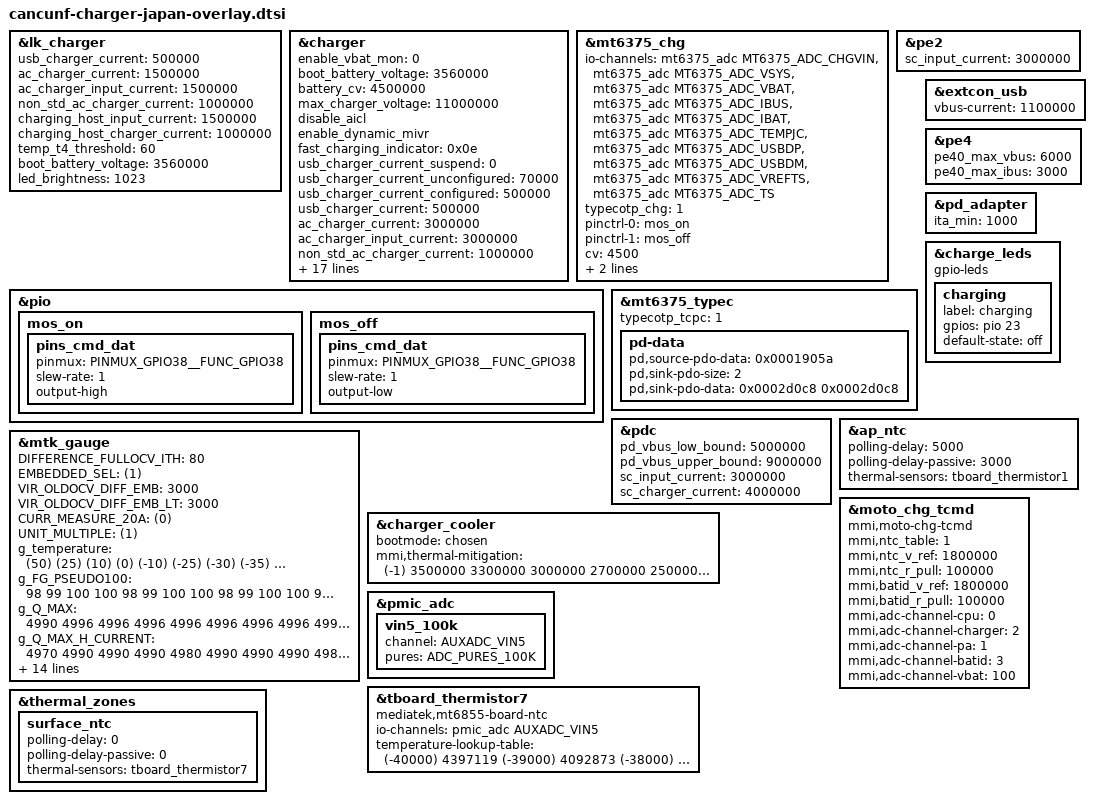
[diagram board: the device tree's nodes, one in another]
/*
 * Copyright (c) 2021 MediaTek Inc.
 *
 * This program is free software; you can redistribute it and/or modify
 * it under the terms of the GNU General Public License version 2 as
 * published by the Free Software Foundation.
 *
 * This program is distributed in the hope that it will be useful,
 * but WITHOUT ANY WARRANTY; without even the implied warranty of
 * MERCHANTABILITY or FITNESS FOR A PARTICULAR PURPOSE.  See the
 * GNU General Public License for more details.
 */

#include <dt-bindings/iio/adc/mediatek,mt6375_adc.h>

&lk_charger {
	/* charging current */
	usb_charger_current = <500000>;
	ac_charger_current = <1500000>;
	ac_charger_input_current = <1500000>;
	non_std_ac_charger_current = <1000000>;
	charging_host_input_current = <1500000>;
	charging_host_charger_current = <1000000>;

	temp_t4_threshold = <60>;

	boot_battery_voltage = <3560000>;
};

&charger {
        /* sw jeita */
        enable_vbat_mon = <0>;

	/* common */
        boot_battery_voltage = <3560000>;
	battery_cv = <4500000>;
	max_charger_voltage = <11000000>;
//	min_charger_voltage = <4600000>;

        disable_aicl;
        enable_dynamic_mivr;

	/*pdc && pe2*/
	fast_charging_indicator = <0x0e>;
	/*swchg + 1CP*/
	//charger_configuration= <3>;

	/* charging current */
	usb_charger_current_suspend = <0>;
	usb_charger_current_unconfigured = <70000>;
	usb_charger_current_configured = <500000>;
	usb_charger_current = <500000>;
	ac_charger_current = <3000000>;
	ac_charger_input_current = <3000000>;
	non_std_ac_charger_current = <1000000>;
	charging_host_charger_current = <1500000>;
	apple_1_0a_charger_current = <650000>;
	apple_2_1a_charger_current = <800000>;
	ta_ac_charger_current = <2000000>;
	typec_limit_aicr = <3000000>;
	typecotp_charger = <1>;

	/*mmi config*/
	mmi,iterm-ma = <243>;
	mmi,mmi-temp-zones = <0 4200 1000 0>,
			<10 4500 3000 1000>,
			<15 4500 3000 3000>,
			<45 4500 4000 4000>,
			<60 4200 4000 0>;
	mmi,mmi-ffc-zones = <0 4200 243>,
			<10 4500 243>,
			<15 4500 243>,
			<25 4530 506>,
			<35 4530 560>,
			<45 4530 965>,
			<60 4200 243>;
	mmi,enable-charging-limit;
	mmi,upper-limit-capacity = <75>;
	mmi,lower-limit-capacity = <70>;
	mmi,min-cp-therm-current-ua = <1600000>;
};

&mt6375_chg {
		io-channels = <&mt6375_adc MT6375_ADC_CHGVIN>,
				      <&mt6375_adc MT6375_ADC_VSYS>,
				      <&mt6375_adc MT6375_ADC_VBAT>,
				      <&mt6375_adc MT6375_ADC_IBUS>,
				      <&mt6375_adc MT6375_ADC_IBAT>,
				      <&mt6375_adc MT6375_ADC_TEMPJC>,
				      <&mt6375_adc MT6375_ADC_USBDP>,
				      <&mt6375_adc MT6375_ADC_USBDM>,
		              <&mt6375_adc MT6375_ADC_VREFTS>,
					  <&mt6375_adc MT6375_ADC_TS>;
		typecotp_chg = <1>;
		pinctrl-names = "mos_on","mos_off";
		pinctrl-0 = <&mos_on>;
		pinctrl-1 = <&mos_off>;

	cv = <4500>;
	ircmp_r = <0>;
	ircmp_v = <0>;
};

&pio {
	mos_on: mos_on {
		pins_cmd_dat {
			pinmux = <PINMUX_GPIO38__FUNC_GPIO38>;
			slew-rate = <1>;
			output-high;
		};
	};
	mos_off: mos_off {
		pins_cmd_dat {
			pinmux = <PINMUX_GPIO38__FUNC_GPIO38>;
			slew-rate = <1>;
			output-low;
		};
	};
};
/*
&pdc {
	sc_input_current = <3000000>;
};
*/
&pe2 {
	sc_input_current = <3000000>;
};

&mt6375_typec {
	typecotp_tcpc = <1>;
	pd-data {
		/* 5V, 900ma */
		pd,source-pdo-data = <0x0001905a>;
		/* 9V, 2A */
		pd,sink-pdo-size = <2>;
                pd,sink-pdo-data = <0x0002d0c8 0x0002d0c8> ;
	};
};

&extcon_usb {
	vbus-current = <1100000>;
};


&pdc {
	pd_vbus_low_bound = <5000000>;
	pd_vbus_upper_bound = <9000000>;

	sc_input_current = <3000000>;
	sc_charger_current = <4000000>;
};



&pe4 {
	pe40_max_vbus = <6000>;
	pe40_max_ibus = <3000>;
};


&pd_adapter{
	ita_min = <1000>;
};

&mtk_gauge {

	DIFFERENCE_FULLOCV_ITH = <80>;  /*gauge cut-off current, should overtop ieoc 50ma*/
	EMBEDDED_SEL = <(1)>;  /*embedded battery,don't remove the battery for user*/
	VIR_OLDOCV_DIFF_EMB = <3000>; /*0.1mv*/
	VIR_OLDOCV_DIFF_EMB_LT = <3000>; /*0.1mv*/
        CURR_MEASURE_20A = <(0)>;
        UNIT_MULTIPLE = <(1)>;

	/* battery prop */
	g_temperature = <(50) (25) (10) (0) (-10) (-25) (-30) (-35) (-40) (-45)>;
	g_FG_PSEUDO100 = <98 99 100 100
		98 99 100 100
		98 99 100 100
		98 99 100 100
		98 99 100 100
		100 100 100 100
		100 100 100 100
		100 100 100 100
		100 100 100 100
		100 100 100 100>;

	g_Q_MAX = <4990 4996 4996 4996
		4996 4996 4996 4996
		4996 4996 4996 4996
		4996 4996 4996 4996
		4990 4996 4996 4996
		4990 4996 4996 4996
		4990 4996 4996 4996
		4990 4996 4996 4996
		4990 4996 4996 4996
		4990 4996 4996 4996>;

	g_Q_MAX_H_CURRENT = <4970 4990 4990 4990
		4980 4990 4990 4990
		4980 4990 4990 4990
		4980 4990 4990 4990
		4970 4990 4990 4990
		4970 4990 4990 4990
		4970 4990 4990 4990
		4970 4990 4990 4990
		4970 4990 4990 4990
		4970 4990 4990 4990>;

	/*vboot voltage for gauge 0%*/
	g_PMIC_MIN_VOL_row = <4>;
	g_PMIC_MIN_VOL_col = <10>;
	g_PMIC_MIN_VOL = <32000  32000  33500  33500
		32000  32000  33000  33000
		33000  33000  33000  33000
		32200  32200  32200  32200
		31360  31360  31360  31360
		31000  31000  31000  31000
		31000  31000  31000  31000
		31000  31000  31000  31000
		31000  31000  31000  31000
		31000  31000  31000  31200>;

	/*Pseudo1 hide percentage*/
	g_QMAX_SYS_VOL_row = <4>;
	g_QMAX_SYS_VOL_col = <10>;
	g_QMAX_SYS_VOL = <32500  32500  34950  34950
		32500  32500  34950  34950
		34250  34250  34250  34250
		34250  34250  34250  34250
		34250  34250  34250  34250
		34250  34250  34250  34250
		32800  32800  32800  32800
		32800  32800  32800  32800
		32800  32800  32800  32800
		32800  32800  32800  32800>;

	SHUTDOWN_1_TIME = <(30)>;
	ACTIVE_TABLE = <(5)>;
	R_FG_VALUE = <(5)>;
	NO_BAT_TEMP_COMPENSATE = <(1)>;
//	df-serialnum = "SB18D61156";
	df-serialnum = "SB18D86478";
	CAR_TUNE_VALUE = <(99)>;
	#include "bat_setting/mt6855_battery_pc50_atl_5000mah.dtsi"
	#include "bat_setting/mt6855_battery_pc50_scud_5000mah.dtsi"
//	#include "bat_setting/mt6855_battery_table_lwn_5000.dtsi"
//	#include "bat_setting/mt6855_battery_table_ff.dtsi"

};

/*
&i2c9 {
       status = "okay";
       sc8551-charger@66{
               compatible = "sc,sc8551-standalone";
               reg = <0x66>;
               sc,sc8551,irq-gpio = <&pio 0 0>;
               sc,sc8551,bat-ovp-disable = <0>;
               sc,sc8551,bat-ocp_disable = <0>;
               sc,sc8551,bus-ocp-disable = <0>;

*/
               /*sc,sc8551,bat-ovp-disable = <0>;
               sc,sc8551,bat-ocp_disable = <0>;
               sc,sc8551,bus-ocp-disable = <0>;*/
/*
               sc,sc8551,bat-ovp-threshold = <4600>;
               sc,sc8551,bat-ocp-threshold = <8000>;

               sc,sc8551,bus-ovp-threshold = <12000>;
               sc,sc8551,bus-ocp-threshold = <3750>;

               sc,sc8551,ac-ovp-threshold = <12000>;
               sc,sc8551,sense-resistor-mohm = <5>;
       };
};
*/

&charge_leds {
	compatible = "gpio-leds";

	charging {
		label = "charging";
		gpios = <&pio 23 0x0>;
		default-state = "off";
	};
};

&charger_cooler {
	bootmode = <&chosen>;
	mmi,thermal-mitigation = <(-1) 3500000 3300000 3000000 2700000 2500000 2200000 2000000 1800000
				1500000 1000000 800000 500000>;
};


&ap_ntc {
	polling-delay = <5000>;
	polling-delay-passive = <3000>;
 	thermal-sensors = <&tboard_thermistor1>;
};


&moto_chg_tcmd {
	compatible = "mmi,moto-chg-tcmd";
	status = "okay";

	mmi,ntc_table = <1>;
	mmi,ntc_v_ref = <1800000>;
	mmi,ntc_r_pull = <100000>;

	mmi,batid_v_ref = <1800000>;
	mmi,batid_r_pull = <100000>;

	mmi,adc-channel-cpu = <0>;
	mmi,adc-channel-charger = <2>;
	mmi,adc-channel-pa = <1>;
	mmi,adc-channel-batid = <3>;
	mmi,adc-channel-vbat = <100>;
};

&lk_charger {
       /* LCD brightness*/
       led_brightness = <1023>;
};

&pmic_adc {
	vin5_100k {
		channel = <AUXADC_VIN5>;
		pures = <ADC_PURES_100K>;
	};
};

&tboard_thermistor7 {
	compatible = "mediatek,mt6855-board-ntc";
	status = "okay";
	#thermal-sensor-cells = <0>;
	io-channels = <&pmic_adc AUXADC_VIN5>;
	io-channel-names = "Surface_NTC";
	temperature-lookup-table = <
		(-40000) 4397119
		(-39000) 4092873
		(-38000) 3811717
		(-37000) 3551748
		(-36000) 3311235
		(-35000) 3088598
		(-34000) 2882395
		(-33000) 2691309
		(-32000) 2514137
		(-31000) 2349777
		(-30000) 2197225
		(-29000) 2055557
		(-28000) 1923931
		(-27000) 1801573
		(-26000) 1687773
		(-25000) 1581880
		(-24000) 1483099
		(-23000) 1391113
		(-22000) 1305412
		(-21000) 1225530
		(-20000) 1151036
		(-19000) 1081535
		(-18000) 1016661
		(-17000) 956079
		(-16000) 899480
		(-15000) 846578
		(-14000) 797111
		(-13000) 750834
		(-12000) 707523
		(-11000) 666972
		(-10000) 628988
		(-9000) 593342
		(-8000) 559930
		(-7000) 528601
		(-6000) 499212
		(-5000) 471632
		(-4000) 445771
		(-3000) 421479
		(-2000) 398652
		(-1000) 377192
		0 357011
		1000 338005
		2000 320121
		3000 303286
		4000 287433
		5000 272499
		6000 258426
		7000 245160
		8000 232649
		9000 220847
		10000 209710
		11000 199196
		12000 189268
		13000 179890
		14000 171027
		15000 162651
		16000 154726
		17000 147232
		18000 140142
		19000 133432
		20000 127080
		21000 121066
		22000 115368
		23000 109970
		24000 104852
		25000 100000
		26000 95398
		27000 91032
		28000 86889
		29000 82956
		30000 79222
		31000 75675
		32000 72306
		33000 69104
		34000 66061
		35000 63167
		36000 60415
		37000 57797
		38000 55306
		39000 52934
		40000 50677
		41000 48528
		42000 46482
		43000 44533
		44000 42675
		45000 40904
		46000 39213
		47000 37601
		48000 36063
		49000 34595
		50000 33195
		51000 31859
		52000 30584
		53000 29366
		54000 28203
		55000 27091
		56000 26028
		57000 25013
		58000 24042
		59000 23113
		60000 22224
		61000 21374
		62000 20560
		63000 19782
		64000 19036
		65000 18322
		66000 17640
		67000 16986
		68000 16360
		69000 15759
		70000 15184
		71000 14631
		72000 14100
		73000 13591
		74000 13103
		75000 12635
		76000 12187
		77000 11756
		78000 11343
		79000 10946
		80000 10565
		81000 10199
		82000 9847
		83000 9509
		84000 9184
		85000 8872
		86000 8572
		87000 8283
		88000 8005
		89000 7738
		90000 7481
		91000 7234
		92000 6997
		93000 6769
		94000 6548
		95000 6337
		96000 6132
		97000 5934
		98000 5744
		99000 5561
		100000 5384
		101000 5214
		102000 5051
		103000 4893
		104000 4741
		105000 4594
		106000 4453
		107000 4316
		108000 4184
		109000 4057
		110000 3934
		111000 3816
		112000 3701
		113000 3591
		114000 3484
		115000 3380
		116000 3281
		117000 3185
		118000 3093
		119000 3003
		120000 2916
		121000 2832
		122000 2751
		123000 2672
		124000 2596
		125000 2522>;
};

&thermal_zones{
		surface_ntc: surface_ntc {
			polling-delay = <0>; /* milliseconds */
			polling-delay-passive = <0>; /* milliseconds */
			thermal-sensors = <&tboard_thermistor7>;
		};
};
